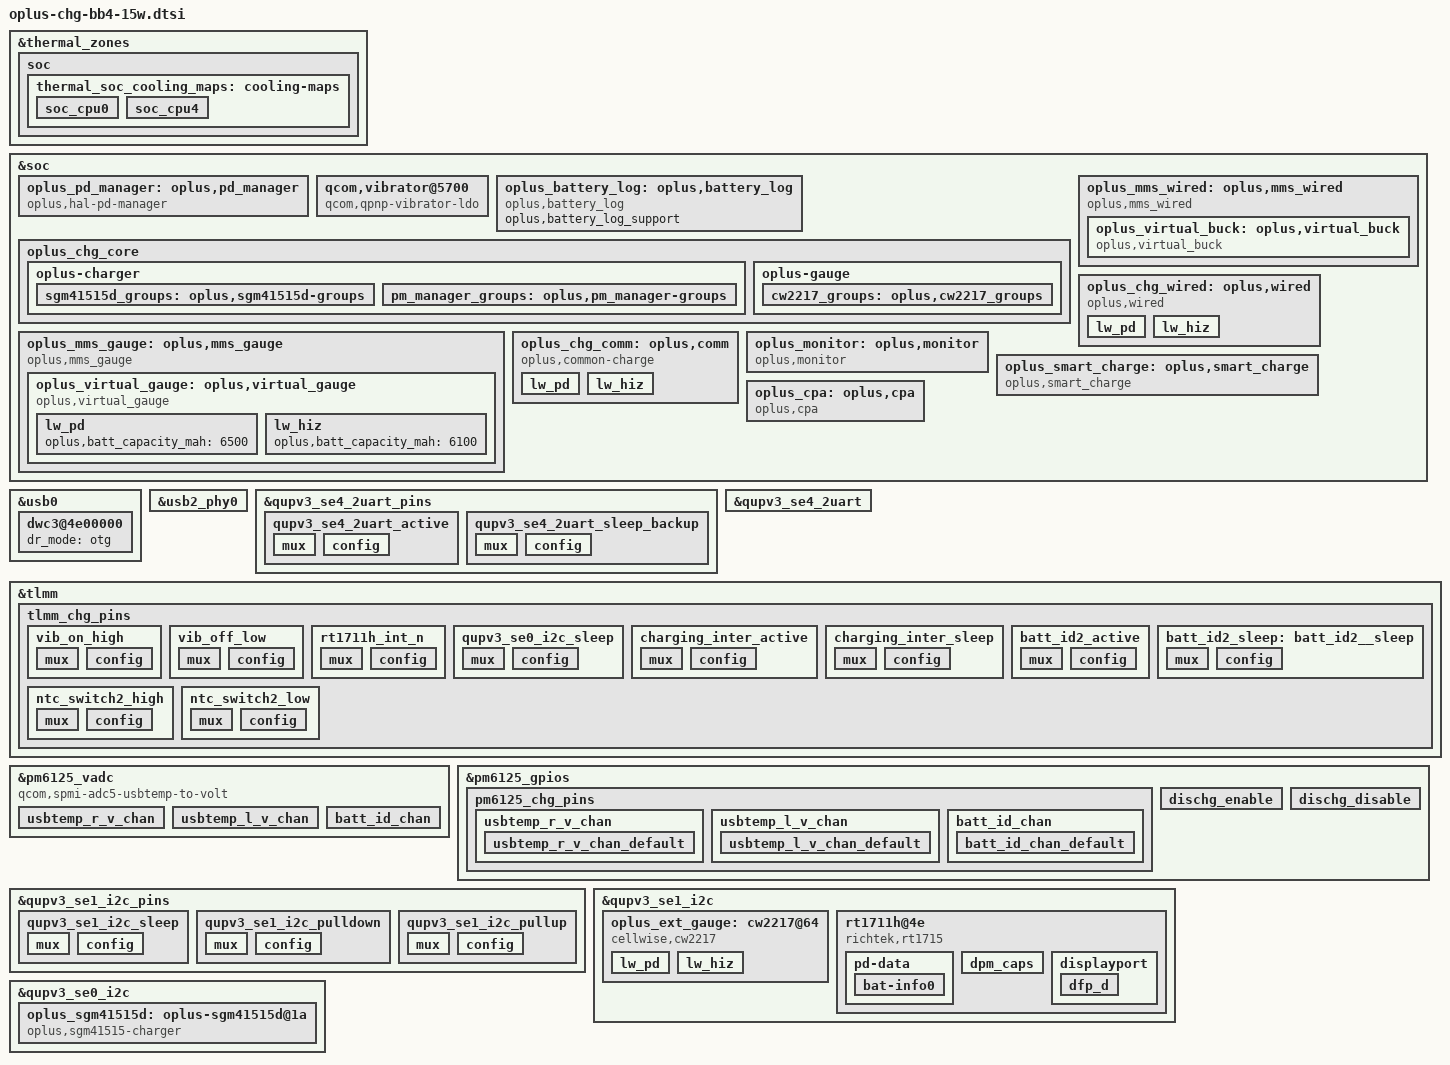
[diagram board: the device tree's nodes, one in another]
#include <dt-bindings/iio/qti_power_supply_iio.h>
#include "oplus-chg-6225.h.dtsi"

&thermal_zones {
	soc {
		thermal_soc_cooling_maps: cooling-maps {
			soc_cpu0 {
				cooling-device =
					<&CPU0 (THERMAL_MAX_LIMIT-4)
						(THERMAL_MAX_LIMIT-4)>;
			};

			soc_cpu4 {
				cooling-device =
					<&CPU4 (THERMAL_MAX_LIMIT-4)
						(THERMAL_MAX_LIMIT-4)>;
			};
		};
	};
};

&soc {
	oplus_pd_manager: oplus,pd_manager{
		compatible = "oplus,hal-pd-manager";
		oplus,ic_type = <OPLUS_CHG_IC_TYPEC>;
		oplus,ic_index = <0>;
		oplus,enable_tcpc_irq;
	};
};

&usb0 {
	dpdm-supply = <&usb2_phy0>;
	extcon = <&oplus_pd_manager>;
	#io-channel-cells = <1>;
	dwc3@4e00000 {
		dr_mode = "otg";
	};
};

&usb2_phy0 {
	qcom,param-override-seq =
		<0x67 0x6c	/* override_x0 */
		 0x87 0x70	/* override_x1 */
		 0x2e 0x74	/* override x2 */
		 0x03 0x78>;	/* override x3 */
	qcom,param-override-seq-host =
		<0x67 0x6c	/* override_x0 */
		 0xcd 0x70	/* override_x1 */
		 0x2e 0x74	/* override x2 */
		 0x03 0x78>;	/* override x3 */
};

&qupv3_se4_2uart_pins{
	qupv3_se4_2uart_active: qupv3_se4_2uart_active {
		mux {
			pins = "gpio12", "gpio13";
			function = "qup4";
		};

		config {
			pins = "gpio12", "gpio13";
			drive-strength = <2>;
			bias-disable;
		};
	};

	qupv3_se4_2uart_sleep_backup: qupv3_se4_2uart_sleep_backup {
		mux {
			pins = "gpio12", "gpio13";
			function = "gpio";
		};

		config {
			pins = "gpio12", "gpio13";
			drive-strength = <2>;
			bias-disable;
			input-enable;
		};
	};
};

&qupv3_se4_2uart {
	pinctrl-names = "default", "sleep";
	pinctrl-0 = <&qupv3_se4_2uart_active>;
	pinctrl-1 = <&qupv3_se4_2uart_sleep_backup>;
	status = "ok";
};

&tlmm {
	tlmm_chg_pins: tlmm_chg_pins {
		vib_on_high: vib_on_high {
			mux {
				pins = "gpio100";
				function = "gpio";
			};

			config {
				pins = "gpio100";
				drive-strength = <2>;
				output-high;
			};
		};
		vib_off_low: vib_off_low {
			mux {
				pins = "gpio100";
				function = "gpio";
			};

			config {
				pins = "gpio100";
				drive-strength = <2>;
				output-low;
			};
		};
		rt1711h_int_n: rt1711h_int_n {
			mux {
				pins = "gpio89";
				function = "gpio";
			};

			config {
				pins = "gpio89";
				drive-strength = <2>;
				bias-disable;
			};
		};

		qupv3_se0_i2c_sleep: qupv3_se0_i2c_sleep {
				mux {
					pins = "gpio0", "gpio1";
					function = "gpio";
				};

				config {
					pins = "gpio0", "gpio1";
					drive-strength = <2>;
					bias-no-pull;
					output-high;
				};
		};

		charging_inter_active: charging_inter_active {
				mux {
				pins = "gpio32";
				function = "gpio";
			};

			config {
				pins = "gpio32";
				drive-strength = <2>;
				bias-pull-up;
			};
		};

		charging_inter_sleep: charging_inter_sleep {
			mux {
				pins = "gpio32";
				function = "gpio";
			};

			config {
				pins = "gpio32";
				drive-strength = <2>;
				bias-pull-up;
			};
		};

		batt_id2_active: batt_id2_active {
				mux {
				pins = "gpio97";
				function = "gpio";
			};

			config {
				pins = "gpio97";
				drive-strength = <2>;
				bias-pull-up;
			};
		};

		batt_id2_sleep: batt_id2__sleep {
			mux {
				pins = "gpio97";
				function = "gpio";
			};

			config {
				pins = "gpio97";
				drive-strength = <2>;
				bias-pull-up;
			};
		};

		ntc_switch2_high: ntc_switch2_high {
			mux {
				pins = "gpio101";
				function = "gpio";
			};

			config {
				pins = "gpio101";
				drive-strength = <2>;
				output-high;
			};
		};

		ntc_switch2_low: ntc_switch2_low {
			mux {
				pins = "gpio101";
				function = "gpio";
			};

			config {
				pins = "gpio101";
				drive-strength = <2>;
				output-low;
			};
		};

	};
};

&pm6125_vadc {
	compatible = "qcom,spmi-adc5-usbtemp-to-volt";
	pinctrl-0 = <&usbtemp_r_v_chan_default &usbtemp_l_v_chan_default &batt_id_chan_default>;
	usbtemp_r_v_chan {
		reg = <ADC5_GPIO1_100K_PU>;
		label = "usbtemp_r_v_chan";
		qcom,ratiometric;
		qcom,hw-settle-time = <200>;
		qcom,pre-scaling = <1 1>;
		qcom,scale-fn-type = <ADC_SCALE_HW_CALIB_DEFAULT>;
	};

	usbtemp_l_v_chan {
		reg = <ADC5_GPIO2_100K_PU>;
		label = "usbtemp_l_v_chan";
		qcom,ratiometric;
		qcom,hw-settle-time = <200>;
		qcom,pre-scaling = <1 1>;
		qcom,scale-fn-type = <ADC_SCALE_HW_CALIB_DEFAULT>;
	};

	batt_id_chan {
		reg = <ADC5_GPIO3_100K_PU>;
		label = "batt_id_chan";
		qcom,scale-fn-type = <ADC_SCALE_HW_CALIB_DEFAULT>;
		qcom,hw-settle-time = <200>;
		qcom,pre-scaling = <1 1>;
	};
};

&pm6125_gpios {
	pm6125_chg_pins: pm6125_chg_pins {
		usbtemp_r_v_chan {
			usbtemp_r_v_chan_default: usbtemp_r_v_chan_default {
				pins = "gpio3";
				bias-high-impedance;
			};
		};

		usbtemp_l_v_chan {
			usbtemp_l_v_chan_default: usbtemp_l_v_chan_default {
				pins = "gpio4";
				bias-high-impedance;
			};
		};

		batt_id_chan {
			batt_id_chan_default: batt_id_chan_default {
				pins = "gpio6";
				bias-high-impedance;
			};
		};

	};
	dischg_enable: dischg_enable {
		pins = "gpio8";
		function = "normal";
		power-source = <0>;
		output-high;
		input-disable;
		qcom,drive-strength = <2>;
	};

	dischg_disable: dischg_disable {
		pins = "gpio8";
		function = "normal";
		power-source = <0>;
		output-low;
		input-disable;
		qcom,drive-strength = <2>;
	};
};

&qupv3_se1_i2c_pins {
	qupv3_se1_i2c_sleep: qupv3_se1_i2c_sleep {
		mux {
			pins = "gpio4", "gpio5";
			function = "gpio";
		};

		config {
			pins = "gpio4", "gpio5";
			drive-strength = <2>;
			bias-no-pull;
			output-high;
		};
	};
	qupv3_se1_i2c_pulldown: qupv3_se1_i2c_pulldown {
		mux {
			pins = "gpio4", "gpio5";
			function = "gpio";
		};

		config {
			pins = "gpio4", "gpio5";
			drive-strength = <2>;
			bias-pull-down;
			output-low;
		};
	};

	qupv3_se1_i2c_pullup: qupv3_se1_i2c_pullup {
		mux {
			pins = "gpio4", "gpio5";
			function = "gpio";
		};

		config {
			pins = "gpio4", "gpio5";
			drive-strength = <2>;
			bias-pull-up;
			input-enable;
		};
	};
};

&qupv3_se1_i2c {
	status = "okay";
	qcom,clk-freq-out = <400000>;
	pinctrl-names = "default", "sleep", "pulldown", "pullup";
	pinctrl-0 = <&qupv3_se1_i2c_active>;
	pinctrl-1 = <&qupv3_se1_i2c_sleep>;
	pinctrl-2 = <&qupv3_se1_i2c_pulldown>;
	pinctrl-3 = <&qupv3_se1_i2c_pullup>;
	oplus_ext_gauge:cw2217@64 {
		status = "okay";
		compatible = "cellwise,cw2217";
		reg = <0x64>;
		oplus,ic_index = <0>;
		oplus,ic_type = <OPLUS_CHG_IC_GAUGE>;
		qcom,cw_ui_full = <100>;
		qcom,cw_user_rsense = <5000>;
		qcom,cw_switch_config_profile;
		oplus,batt_num = <1>;
		qcom,design_capacity = <6100>;
		qcom,rated_capacity = <6100>;
		io-channels = <&pm6125_vadc ADC5_GPIO3_100K_PU>;
		io-channel-names = "batt_id_chan";
		dep-supply = <&pm6125_vadc>;
		oplus,batt_id2_gpio = <&tlmm 97 0x0>;
		pinctrl-names = "batt_id2_active", "batt_id2_sleep", "ntc_switch2_high", "ntc_switch2_low";
		pinctrl-0 = <&batt_id2_active>;
		pinctrl-1 = <&batt_id2_sleep>;
		pinctrl-2 = <&ntc_switch2_high>;
		pinctrl-3 = <&ntc_switch2_low>;
		batid_voltage_range = <70 180>;

		qcom,config_profile_data0 = /bits/ 8 <
			0x46 0x00 0x00 0x00 0x00 0x00 0x00 0x00
			0xA3 0xBE 0xBC 0xC2 0xAC 0xA3 0xD6 0xC3
			0xB2 0xF6 0xD2 0x9C 0x81 0x61 0x51 0x44
			0x3A 0x32 0x29 0x98 0x94 0xDF 0xD1 0xFF
			0xDB 0xD4 0xD7 0xD6 0xD2 0xD1 0xCE 0xCA
			0xC4 0xC3 0xD0 0xBE 0x9A 0x8F 0x84 0x75
			0x65 0x62 0x7C 0x8C 0x9D 0xA7 0x6F 0x62
			0x20 0x00 0xAB 0x10 0x00 0xB3 0x52 0x02
			0x00 0x00 0x64 0x12 0xC2 0x24 0x00 0x00
			0x00 0x00 0x00 0x00 0x00 0x00 0x00 0xA1>;
		qcom,config_profile_data1 = /bits/ 8 <
			0x46 0x00 0x00 0x00 0x00 0x00 0x00 0x00
			0xA3 0xBE 0xBC 0xC2 0xAC 0xA3 0xD6 0xC3
			0xB2 0xF6 0xD2 0x9C 0x81 0x61 0x51 0x44
			0x3A 0x32 0x29 0x98 0x94 0xDF 0xD1 0xFF
			0xDB 0xD4 0xD7 0xD6 0xD2 0xD1 0xCE 0xCA
			0xC4 0xC3 0xD0 0xBE 0x9A 0x8F 0x84 0x75
			0x65 0x62 0x7C 0x8C 0x9D 0xA7 0x6F 0x62
			0x20 0x00 0xAB 0x10 0x00 0xB3 0x52 0x02
			0x00 0x00 0x64 0x12 0xC2 0x24 0x00 0x00
			0x00 0x00 0x00 0x00 0x00 0x00 0x00 0xA1>;

		lw_pd {
			qcom,cw_switch_config_profile;
			oplus,batt_num = <1>;
			qcom,cw_ui_full = <100>;
			qcom,cw_user_rsense = <5000>;
			qcom,design_capacity = <6500>;
			qcom,rated_capacity = <6500>;
			batid_voltage_range = <70 180>;
			qcom,config_profile_data0 = /bits/ 8 <
				0x46 0x00 0x00 0x00 0x00 0x00 0x00 0x00
				0xAD 0xB2 0xB4 0xBC 0xA4 0x9F 0xDD 0xC7
				0xB4 0xFF 0xE0 0xA0 0x83 0x6A 0x58 0x4E
				0x49 0x48 0x47 0xBF 0xA9 0xDF 0xAA 0xFA
				0xD5 0xD3 0xD9 0xD6 0xD2 0xD1 0xCF 0xCA
				0xC5 0xC5 0xCC 0xC2 0x99 0x8F 0x82 0x73
				0x63 0x60 0x6F 0x8B 0xA0 0x9C 0x88 0x62
				0x20 0x00 0xAB 0x10 0x00 0xB2 0xBF 0x02
				0x00 0x00 0x64 0x16 0xC1 0xA9 0x00 0x00
				0x00 0x00 0x00 0x00 0x00 0x00 0x00 0x80>;
			qcom,config_profile_data1 = /bits/ 8 <
				0x46 0x00 0x00 0x00 0x00 0x00 0x00 0x00
				0xAD 0xB2 0xB4 0xBC 0xA4 0x9F 0xDD 0xC7
				0xB4 0xFF 0xE0 0xA0 0x83 0x6A 0x58 0x4E
				0x49 0x48 0x47 0xBF 0xA9 0xDF 0xAA 0xFA
				0xD5 0xD3 0xD9 0xD6 0xD2 0xD1 0xCF 0xCA
				0xC5 0xC5 0xCC 0xC2 0x99 0x8F 0x82 0x73
				0x63 0x60 0x6F 0x8B 0xA0 0x9C 0x88 0x62
				0x20 0x00 0xAB 0x10 0x00 0xB2 0xBF 0x02
				0x00 0x00 0x64 0x16 0xC1 0xA9 0x00 0x00
				0x00 0x00 0x00 0x00 0x00 0x00 0x00 0x80>;
		};
		lw_hiz {
			qcom,cw_switch_config_profile;
			oplus,batt_num = <1>;
			qcom,cw_ui_full = <100>;
			qcom,cw_user_rsense = <5000>;
			qcom,design_capacity = <6100>;
			qcom,rated_capacity = <6100>;
			batid_voltage_range = <70 180>;
			qcom,config_profile_data0 = /bits/ 8 <
				0x46 0x00 0x00 0x00 0x00 0x00 0x00 0x00
				0xA3 0xBE 0xBC 0xC2 0xAC 0xA3 0xD6 0xC3
				0xB2 0xF6 0xD2 0x9C 0x81 0x61 0x51 0x44
				0x3A 0x32 0x29 0x98 0x94 0xDF 0xD1 0xFF
				0xDB 0xD4 0xD7 0xD6 0xD2 0xD1 0xCE 0xCA
				0xC4 0xC3 0xD0 0xBE 0x9A 0x8F 0x84 0x75
				0x65 0x62 0x7C 0x8C 0x9D 0xA7 0x6F 0x62
				0x20 0x00 0xAB 0x10 0x00 0xB3 0x52 0x02
				0x00 0x00 0x64 0x12 0xC2 0x24 0x00 0x00
				0x00 0x00 0x00 0x00 0x00 0x00 0x00 0xA1>;
			qcom,config_profile_data1 = /bits/ 8 <
				0x46 0x00 0x00 0x00 0x00 0x00 0x00 0x00
				0xA3 0xBE 0xBC 0xC2 0xAC 0xA3 0xD6 0xC3
				0xB2 0xF6 0xD2 0x9C 0x81 0x61 0x51 0x44
				0x3A 0x32 0x29 0x98 0x94 0xDF 0xD1 0xFF
				0xDB 0xD4 0xD7 0xD6 0xD2 0xD1 0xCE 0xCA
				0xC4 0xC3 0xD0 0xBE 0x9A 0x8F 0x84 0x75
				0x65 0x62 0x7C 0x8C 0x9D 0xA7 0x6F 0x62
				0x20 0x00 0xAB 0x10 0x00 0xB3 0x52 0x02
				0x00 0x00 0x64 0x12 0xC2 0x24 0x00 0x00
				0x00 0x00 0x00 0x00 0x00 0x00 0x00 0xA1>;
		};
	};

	rt1711h@4e {
		compatible = "richtek,rt1715";
		reg = <0x4e>;
		status = "okay";
		tcpc-dual,supported_modes = <0>; /* 0: dfp/ufp, */
						 /* 1: dfp, 2: ufp */
		rt-tcpc,name = "type_c_port0"; /* tcpc_device's name */
		rt-tcpc,role_def = <1>; /* 0: Unknown, 1: SNK, 2: SRC */
					/* 3: DRP, 4: Try.SRC, 5: Try.SNK */
		rt-tcpc,rp_level = <0>; /* 0: Default, 1: 1.5, 2: 3.0 */
		rt1711pd,intr_gpio = <&tlmm 89 0x0>;
		rt1711pd,intr_gpio_num = <89>;
		rt,disable_irq_reset;
		charger = <&oplus_sgm41515d>;
		pinctrl-names = "default";
		pinctrl-0 = <&rt1711h_int_n>;
		pd-data {
			pd,vid = <0x29cf>;
			pd,pid = <0x1711>;
			pd,source-cap-ext = /bits/ 8 <0xcf 0x29 0x11 0x17
						      0x00 0x00 0x00 0x00
						      0x00 0x00 0x00 0x00
						      0x00 0x00 0x00 0x00
						      0x00 0x00 0x00 0x00
						      0x00 0x00 0x01 0x02
						      0x00>;
			pd,sink-cap-ext = /bits/ 8 <0xcf 0x29 0x11 0x17
					0x00 0x00 0x00 0x00
					0x01 0x00 0x00 0x00
					0x00 0x00 0x00 0x00
					0x01 0x00 0x00 0x00
					0x00 0x00 0x00 0x00>;
			pd,mfrs = "RichtekTCPC";

			/*
			 *	VSAFE5V = 0, MAX_POWER = 1, CUSTOM = 2,
			 *	MAX_POWER_LV = 0x21, MAX_POWER_LVIC = 0x31
			 *	MAX_POWER_HV = 0x41, MAX_POWER_HVIC = 0x51
			 */
			pd,charging_policy = <0>;

			/*
			 * Fixed 5V, 500 mA <0x00019032>
			 * Fixed 5V, 1A <0x00019064>
			 * Fixed 5V, 2A <0x000190c8>
			 * Fixed 5V, 3A <0x0001912c>
			 * Fixed 9V, 500 mA <0x0002d032>
			 * Fixed 9V, 1A <0x0002d064>
			 * Fixed 9V, 2A <0x0002d0c8>
			 * Fixed 9V, 3A <0x0002d12c>
			 * Variable 5-9V, 1A <0x8642d064>
			 * Variable 5-9V, 2A <0x8642d0c8>
			 * Variable 5-9V, 3A <0x8642d12c>
			 */
			pd,source-pdo-size = <1>;
			pd,source-pdo-data = <0x00019064>;
			pd,sink-pdo-size = <1>;
			pd,sink-pdo-data = <0x0001912c>;

			pd,id-vdo-size = <6>;
			pd,id-vdo-data = <0xd14029cf 0x0 0x17110000
					  0x61000000 0x0 0x41000000>;

			bat,nr = <1>;
			pd,country_nr = <0>;

			bat-info0 {
				bat,vid = <0x29cf>;
				bat,pid = <0x1711>;
				bat,mfrs = "bat1";
				bat,design_cap = <3000>;
			};
		};
		dpm_caps {
			local_dr_power;
			local_dr_data;
			local_usb_comm;
			local_no_suspend;
			attempt_discover_cable;
			attempt_discover_id;
			attempt_discover_svid;

			/* 0: disable, 1: prefer_snk, 2: prefer_src */
			pr_check = <0>;
			/* 0: disable, 1: prefer_ufp, 2: prefer_dfp */
			dr_check = <0>;
		};
		displayport {
			/* connection type = "both", "ufp_d", "dfp_d" */
			1st_connection = "dfp_d";
			2nd_connection = "dfp_d";
			signal,dp_v13;
			typec,receptacle;
			dfp_d {
				pin_assignment,mode_c;
				pin_assignment,mode_d;
				pin_assignment,mode_e;
			};
		};
	};
};

/* load vibrator for rm pmic */
&soc {
	qcom,vibrator@5700 {
		compatible = "qcom,qpnp-vibrator-ldo";
		reg = <0x5700 0x100>;
		qcom,vib-ldo-volt-uv = <3000000>;
		qcom,disable-overdrive;
		qcom,vib-type = <1>;	/* 0:ldo 1:gpio */
		status = "okay";
		qcom,vibrator_switch-gpio = <&tlmm 100 0x00>;
		pinctrl-names = "vib_on_high", "vib_off_low";
		pinctrl-0 = <&vib_on_high>;
		pinctrl-1 = <&vib_off_low >;
	};
};

&qupv3_se0_i2c {
	status = "okay";
	pinctrl-0 = <&qupv3_se0_i2c_active>;
	pinctrl-1 = <&qupv3_se0_i2c_sleep>;
	qcom,clk-freq-out = <400000>;
	oplus,i2c-auto-suspend-delay-ms = <3000>;
	oplus_sgm41515d:oplus-sgm41515d@1a {
		status = "okay";
		compatible = "oplus,sgm41515-charger";
		reg = <0x1a>;
		dpdm-supply = <&usb2_phy0>;
		oplus,dischg-gpio = <&pm6125_gpios 8 0x00>;
		oplus,event-gpio = <&tlmm 32 0x00>;
		qcom,ntc-switch-gpio-amux = <&tlmm 101 0x00>;
		pinctrl-names = "event_default", "charging_inter_sleep",
					"dischg_enable", "dischg_disable";
		pinctrl-0 = <&charging_inter_active>;
		pinctrl-1 = <&charging_inter_sleep>;
		pinctrl-2 = <&dischg_enable>;
		pinctrl-3 = <&dischg_disable>;
		oplus,not_support_usb_btb;
		oplus,ic_index = <0>;
		oplus,ic_type = <OPLUS_CHG_IC_BUCK>;
		io-channels = <&pm6125_vadc ADC5_GPIO3_100K_PU>;
		io-channel-names = "chg_temp_adc";
		#include "BB4_ntc.h.dtsi"
	};

};

&soc {
	oplus_battery_log: oplus,battery_log {
		compatible = "oplus,battery_log";
		oplus,battery_log_support;
	};
	oplus_chg_core {
		oplus,chg_framework_v2;
		oplus,smart_charging_screenoff;
		oplus,chg_spec_version = <OPLUS_CHG_SPEC_VER_V3P7>;
		oplus,battery_type_by_cmdline;
		oplus-charger {
			sgm41515d_groups: oplus,sgm41515d-groups {
				functions = <
					OPLUS_IC_FUNC_INIT
					OPLUS_IC_FUNC_EXIT
					OPLUS_IC_FUNC_REG_DUMP
					OPLUS_IC_FUNC_SMT_TEST
					OPLUS_IC_FUNC_BUCK_INPUT_PRESENT
					OPLUS_IC_FUNC_BUCK_INPUT_SUSPEND
					OPLUS_IC_FUNC_BUCK_INPUT_IS_SUSPEND
					OPLUS_IC_FUNC_BUCK_OUTPUT_SUSPEND
					OPLUS_IC_FUNC_BUCK_OUTPUT_IS_SUSPEND
					OPLUS_IC_FUNC_BUCK_SET_ICL
					OPLUS_IC_FUNC_BUCK_GET_ICL
					OPLUS_IC_FUNC_BUCK_SET_FCC
					OPLUS_IC_FUNC_BUCK_SET_FV
					OPLUS_IC_FUNC_BUCK_SET_ITERM
					OPLUS_IC_FUNC_BUCK_SET_RECHG_VOL
					OPLUS_IC_FUNC_BUCK_GET_INPUT_CURR
					OPLUS_IC_FUNC_BUCK_GET_INPUT_VOL
					OPLUS_IC_FUNC_OTG_BOOST_ENABLE
					OPLUS_IC_FUNC_SET_OTG_BOOST_VOL
					OPLUS_IC_FUNC_SET_OTG_BOOST_CURR_LIMIT
					OPLUS_IC_FUNC_BUCK_AICL_ENABLE
					OPLUS_IC_FUNC_BUCK_AICL_RERUN
					OPLUS_IC_FUNC_BUCK_AICL_RESET
					OPLUS_IC_FUNC_BUCK_GET_CHARGER_TYPE
					OPLUS_IC_FUNC_BUCK_RERUN_BC12
					OPLUS_IC_FUNC_BUCK_QC_DETECT_ENABLE
					OPLUS_IC_FUNC_BUCK_SET_QC_CONFIG
					OPLUS_IC_FUNC_BUCK_SHIPMODE_ENABLE
					OPLUS_IC_FUNC_BUCK_GET_USB_BTB_TEMP
					OPLUS_IC_FUNC_BUCK_GET_BATT_BTB_TEMP
					OPLUS_IC_FUNC_BUCK_SET_AICL_POINT
					OPLUS_IC_FUNC_BUCK_HARDWARE_INIT
					OPLUS_IC_FUNC_BUCK_KICK_WDT
					OPLUS_IC_FUNC_POWER_ROLE_SWAP
					OPLUS_IC_FUNC_SET_USB_DISCHG_ENABLE
				>;
				virqs = <
					OPLUS_IC_VIRQ_ERR
					OPLUS_IC_VIRQ_PLUGIN
					OPLUS_IC_VIRQ_CHG_TYPE_CHANGE
					OPLUS_IC_VIRQ_BC12_COMPLETED
				>;
			};
			pm_manager_groups: oplus,pm_manager-groups {
				functions = <
					OPLUS_IC_FUNC_INIT
					OPLUS_IC_FUNC_EXIT
					OPLUS_IC_FUNC_REG_DUMP
					OPLUS_IC_FUNC_SMT_TEST
					OPLUS_IC_FUNC_BUCK_GET_CHARGER_TYPE
					OPLUS_IC_FUNC_BUCK_GET_CC_ORIENTATION
					OPLUS_IC_FUNC_BUCK_SET_PD_CONFIG
					OPLUS_IC_FUNC_GET_TYPEC_ROLE
					OPLUS_IC_FUNC_GET_TYPEC_MODE
					OPLUS_IC_FUNC_SET_TYPEC_MODE
					OPLUS_IC_FUNC_GET_CHARGER_VOL_MAX
					OPLUS_IC_FUNC_GET_CHARGER_VOL_MIN
					OPLUS_IC_FUNC_GET_CHARGER_CURR_MAX
					OPLUS_IC_FUNC_BUCK_BC12_COMPLETED
					OPLUS_IC_FUNC_GET_OTG_ENABLE
					OPLUS_IC_FUNC_IS_OPLUS_SVID
					OPLUS_IC_FUNC_GET_DATA_ROLE
					OPLUS_IC_FUNC_FIXED_PDO_SET
					OPLUS_IC_FUNC_PPS_PDO_SET
					OPLUS_IC_FUNC_PPS_GET_PDO_INFO
				>;
				virqs = <
					OPLUS_IC_VIRQ_ERR
					OPLUS_IC_VIRQ_CHG_TYPE_CHANGE
					OPLUS_IC_VIRQ_SVID
					OPLUS_IC_VIRQ_VOLTAGE_CHANGED
					OPLUS_IC_VIRQ_CURRENT_CHANGED
					OPLUS_IC_VIRQ_OTG_ENABLE
					OPLUS_IC_VIRQ_DATA_ROLE_CHANGED
					OPLUS_IC_VIRQ_PR_SWAP
				>;
			};
		};
		oplus-gauge {
			cw2217_groups: oplus,cw2217_groups {
				functions = <
					OPLUS_IC_FUNC_INIT
					OPLUS_IC_FUNC_EXIT
					OPLUS_IC_FUNC_REG_DUMP
					OPLUS_IC_FUNC_GAUGE_GET_BATT_VOL
					OPLUS_IC_FUNC_GAUGE_GET_BATT_MAX
					OPLUS_IC_FUNC_GAUGE_GET_BATT_MIN
					OPLUS_IC_FUNC_GAUGE_GET_BATT_CURR
					OPLUS_IC_FUNC_GAUGE_GET_BATT_TEMP
					OPLUS_IC_FUNC_GAUGE_GET_BATT_SOC
					OPLUS_IC_FUNC_GAUGE_GET_BATT_FCC
					OPLUS_IC_FUNC_GAUGE_GET_BATT_CC
					OPLUS_IC_FUNC_GAUGE_GET_BATT_RM
					OPLUS_IC_FUNC_GAUGE_GET_BATT_SOH
					OPLUS_IC_FUNC_GAUGE_GET_BATT_AUTH
					OPLUS_IC_FUNC_GAUGE_GET_BATT_HMAC
					OPLUS_IC_FUNC_GAUGE_SET_BATT_FULL
					OPLUS_IC_FUNC_GAUGE_GET_BATT_NUM
					OPLUS_IC_FUNC_GAUGE_GET_DEVICE_TYPE
					OPLUS_IC_FUNC_GAUGE_GET_AFI_UPDATE_DONE
					OPLUS_IC_FUNC_GAUGE_GET_DEVICE_TYPE_FOR_BCC
					OPLUS_IC_FUNC_GAUGE_GET_QMAX
					OPLUS_IC_FUNC_GAUGE_GET_REG_INFO
					OPLUS_IC_FUNC_GAUGE_GET_BATT_EXIST
					OPLUS_IC_FUNC_GAUGE_GET_DEC_FG_TYPE
					OPLUS_IC_FUNC_GAUGE_GET_DEC_CV_SOH
				>;
				virqs = <
					OPLUS_IC_VIRQ_ERR
					OPLUS_IC_VIRQ_OFFLINE
					OPLUS_IC_VIRQ_RESUME
				>;
			};
		};
	};
};

&soc {
	oplus_mms_wired: oplus,mms_wired {
		compatible = "oplus,mms_wired";
		oplus,buck_ic = <&oplus_virtual_buck>;
		oplus,adc_info_name = "855";
		high-temp-scheme;
		oplus_spec,usbtemp_batttemp_gap = <12>;
		oplus,support_usbtemp_protect_v2;
		oplus_spec,usbtemp_batt_temp_low = <50>;
		oplus_spec,usbtemp_batt_temp_high = <50>;
		oplus_spec,usbtemp_batt_temp_over_hot = <60>;
		oplus_spec,usbtemp_ntc_temp_low = <57>;
		oplus_spec,usbtemp_ntc_temp_high = <69>;
		oplus_spec,usbtemp_temp_gap_low_with_batt_temp = <7>;
		oplus_spec,usbtemp_temp_gap_with_batt_temp_in_over_hot = <15>;
		oplus_spec,usbtemp_temp_gap_high_with_batt_temp = <12>;
		oplus_spec,usbtemp_temp_gap_low_without_batt_temp = <12>;
		oplus_spec,usbtemp_temp_gap_high_without_batt_temp = <24>;
		oplus_spec.usbtemp_rise_fast_temp_low = <3>;
		oplus_spec,usbtemp_rise_fast_temp_high = <3>;
		oplus_spec,usbtemp_rise_fast_temp_count_low = <30>;
		oplus_spec,usbtemp_rise_fast_temp_count_high = <20>;
		oplus_spec,usbtemp_cool_down_ntc_low = <54>;
		oplus_spec,usbtemp_cool_down_ntc_high = <65>;
		oplus_spec,usbtemp_cool_down_gap_low = <12>;
		oplus_spec,usbtemp_cool_down_gap_high = <20>;
		oplus_spec,usbtemp_cool_down_recover_ntc_low = <48>;
		oplus_spec,usbtemp_cool_down_recover_ntc_high = <60>;
		oplus_spec,usbtemp_cool_down_recover_gap_low = <6>;
		oplus_spec,usbtemp_cool_down_recover_gap_high = <15>;
		oplus_spec,usbtemp_otg_cc_boot_current_limit = <1500>;
		oplus_virtual_buck: oplus,virtual_buck {
			compatible = "oplus,virtual_buck";
			oplus,buck_ic = <&oplus_sgm41515d &oplus_pd_manager>;
			oplus,buck_ic_index = <0 1>;
			oplus,buck_ic_current_ratio = <100 0>;
			oplus,buck_ic_connect = <OPLUS_CHG_IC_CONNECT_PARALLEL>;
			oplus,main_charger = <0>;
			oplus,buck_ic_func_group = <&sgm41515d_groups &pm_manager_groups>;
			oplus,ic_type = <OPLUS_CHG_IC_VIRTUAL_BUCK>;
			oplus,ic_index = <0>;
			oplus,uart_tx-gpio = <&tlmm 12 0x00>;
			oplus,uart_rx-gpio = <&tlmm 13 0x00>;
			oplus,usbtemp_conversion_ratio = <10>;
			oplus,ntc_switch_usbtemp_r;
			pinctrl-names = "usbtemp_l_gpio_default", "usbtemp_r_gpio_default";
			pinctrl-0 = <&usbtemp_l_v_chan_default>;
			pinctrl-1 = <&usbtemp_r_v_chan_default>;
			io-channels = <&pm6125_vadc ADC5_GPIO2_100K_PU>,
						<&pm6125_vadc ADC5_GPIO1_100K_PU>;
			io-channel-names = "usb_temp_adc_l", "usb_temp_adc_r";
		};
	};
	oplus_mms_gauge: oplus,mms_gauge {
		compatible = "oplus,mms_gauge";
		oplus,gauge_ic = <&oplus_virtual_gauge>;
		oplus,topic-update-interval = <10000>;
		oplus_virtual_gauge: oplus,virtual_gauge {
			compatible = "oplus,virtual_gauge";
			oplus,gauge_ic = <&oplus_ext_gauge>;
			oplus,gauge_ic_index = <0>;
			oplus,gauge_ic_func_group = <&cw2217_groups>;
			oplus,ic_type = <OPLUS_CHG_IC_VIRTUAL_GAUGE>;
			oplus,ic_index = <0>;
			oplus,batt_capacity_mah = <6100>;
			lw_pd {
				oplus,batt_capacity_mah = <6500>;
			};
			lw_hiz {
				oplus,batt_capacity_mah = <6100>;
			};
		};
	};
};

&soc {
	oplus_chg_wired: oplus,wired {
		compatible = "oplus,wired";
		oplus_spec,vbatt_pdqc_to_5v_thr = <4500>;
		oplus_spec,vbatt_pdqc_to_9v_thr = <3000>;
		oplus_spec,pd-iclmax-ma = <3000>;
		oplus_spec,qc-iclmax-ma = <3000>;
		oplus_spec,non-standard-ibatmax-ma = <500>;
		oplus_spec,input-power-mw = <
			2500		/* OPLUS_WIRED_CHG_MODE_UNKNOWN */
			2500		/* OPLUS_WIRED_CHG_MODE_SDP */
			7500		/* OPLUS_WIRED_CHG_MODE_CDP */
			15000		/* OPLUS_WIRED_CHG_MODE_DCP */
			15000		/* OPLUS_WIRED_CHG_MODE_VOOC */
			15000		/* OPLUS_WIRED_CHG_MODE_QC */
			15000		/* OPLUS_WIRED_CHG_MODE_PD */
		>;
		oplus_spec,led_on-fccmax-ma = <0 892 2677 3300 3300 3300 3300 1000 0>;
		oplus_spec,fccmax-ma-lv = <
			0 892 2200 2200 2200 2200 2200 2200 0	/* OPLUS_WIRED_CHG_MODE_UNKNOWN */
			0 600 600  600  600  600  600  600  0	/* OPLUS_WIRED_CHG_MODE_SDP */
			0 892 1600 1600 1600 1600 1600 1600 0	/* OPLUS_WIRED_CHG_MODE_CDP */
			0 892 2677 3300 3300 3300 3300 3272 0	/* OPLUS_WIRED_CHG_MODE_DCP */
			0 892 2677 3300 3300 3300 3300 3272 0	/* OPLUS_WIRED_CHG_MODE_VOOC */
			0 892 2677 3300 3300 3300 3300 3272 0	/* OPLUS_WIRED_CHG_MODE_QC */
			0 892 2677 3300 3300 3300 3300 3272 0	/* OPLUS_WIRED_CHG_MODE_PD */
		>;
		oplus_spec,fccmax-ma-hv = <
			0 892 1487 2200 2200 2200 2200 2200 0	/* OPLUS_WIRED_CHG_MODE_UNKNOWN */
			0 600 600  600  600  600  600  600  0	/* OPLUS_WIRED_CHG_MODE_SDP */
			0 892 1487 1600 1600 1600 1600 1600 0	/* OPLUS_WIRED_CHG_MODE_CDP */
			0 892 1487 3300 3300 3300 3300 3272 0	/* OPLUS_WIRED_CHG_MODE_DCP */
			0 892 1487 3300 3300 3300 3300 3272 0	/* OPLUS_WIRED_CHG_MODE_VOOC */
			0 892 1487 3300 3300 3300 3300 3272 0	/* OPLUS_WIRED_CHG_MODE_QC */
			0 892 1487 3300 3300 3300 3300 3272 0	/* OPLUS_WIRED_CHG_MODE_PD */
		>;
		oplus_spec,cool_down_sale_pdqc_vol_mv = <5000>;
		oplus_spec,cool_down_sale_pdqc_curr_ma = <1200>;
		oplus_spec,cool_down_pdqc_vol_mv = <5000 5000 5000 5000 5000>;
		oplus_spec,cool_down_pdqc_curr_ma = <1200 1500 2000 2500 3000>;
		oplus_spec,cool_down_normal_curr_ma = <1200 1500 2000 2500 3000>;
		oplus_spec,vbus_ov_thr_mv = <10000 10000>;
		oplus_spec,vbus_uv_thr_mv = <4300 4300>;
		oplus,pd_strategy_name = "cgcl";
		oplus,pd_strategy_data = < OPLUS_STRATEGY_USE_SHELL_TEMP
					   0   420 3000 1 0
					   410 430 1500 2 0
					   420 440 1200 2 1>;

		oplus,dcp_strategy_name = "cgcl";
		oplus,dcp_strategy_data = < OPLUS_STRATEGY_USE_SHELL_TEMP
					   0   420 3000 1 0
					   410 430 1500 2 0
					   420 440 1200 2 1>;

		/* id2 pulldown: Single cell */
		lw_pd {
			oplus_spec,vbatt_pdqc_to_5v_thr = <4500>;
			oplus_spec,vbatt_pdqc_to_9v_thr = <3000>;
			oplus_spec,pd-iclmax-ma = <3000>;
			oplus_spec,qc-iclmax-ma = <3000>;
			oplus_spec,non-standard-ibatmax-ma = <500>;
			oplus_spec,input-power-mw = <
				2500		/* OPLUS_WIRED_CHG_MODE_UNKNOWN */
				2500		/* OPLUS_WIRED_CHG_MODE_SDP */
				7500		/* OPLUS_WIRED_CHG_MODE_CDP */
				15000		/* OPLUS_WIRED_CHG_MODE_DCP */
				15000		/* OPLUS_WIRED_CHG_MODE_VOOC */
				15000		/* OPLUS_WIRED_CHG_MODE_QC */
				15000		/* OPLUS_WIRED_CHG_MODE_PD */
			>;
			oplus_spec,led_on-fccmax-ma = <0 950 2850 3300 3300 3300 3300 1000 0>;
			oplus_spec,fccmax-ma-lv = <
				0 950 2200 2200 2200 2200 2200 2200 0	/* OPLUS_WIRED_CHG_MODE_UNKNOWN */
				0 600 600  600  600  600  600  600  0	/* OPLUS_WIRED_CHG_MODE_SDP */
				0 950 1600 1600 1600 1600 1600 1600 0	/* OPLUS_WIRED_CHG_MODE_CDP */
				0 950 2850 3300 3300 3300 3300 3300 0	/* OPLUS_WIRED_CHG_MODE_DCP */
				0 950 2850 3300 3300 3300 3300 3300 0	/* OPLUS_WIRED_CHG_MODE_VOOC */
				0 950 2850 3300 3300 3300 3300 3300 0	/* OPLUS_WIRED_CHG_MODE_QC */
				0 950 2850 3300 3300 3300 3300 3300 0	/* OPLUS_WIRED_CHG_MODE_PD */
			>;
			oplus_spec,fccmax-ma-hv = <
				0 950 1583 2200 2200 2200 2200 2200 0	/* OPLUS_WIRED_CHG_MODE_UNKNOWN */
				0 600 600  600  600  600  600  600  0	/* OPLUS_WIRED_CHG_MODE_SDP */
				0 950 1583 1600 1600 1600 1600 1600 0	/* OPLUS_WIRED_CHG_MODE_CDP */
				0 950 1583 3300 3300 3300 3300 3300 0	/* OPLUS_WIRED_CHG_MODE_DCP */
				0 950 1583 3300 3300 3300 3300 3300 0	/* OPLUS_WIRED_CHG_MODE_VOOC */
				0 950 1583 3300 3300 3300 3300 3300 0	/* OPLUS_WIRED_CHG_MODE_QC */
				0 950 1583 3300 3300 3300 3300 3300 0	/* OPLUS_WIRED_CHG_MODE_PD */
			>;
			oplus_spec,cool_down_sale_pdqc_vol_mv = <5000>;
			oplus_spec,cool_down_sale_pdqc_curr_ma = <1200>;
			oplus_spec,cool_down_pdqc_vol_mv = <5000 5000 5000 5000 5000>;
			oplus_spec,cool_down_pdqc_curr_ma = <1200 1500 2000 2500 3000>;
			oplus_spec,cool_down_normal_curr_ma = <1200 1500 2000 2500 3000>;
			oplus_spec,vbus_ov_thr_mv = <10000 10000>;
			oplus_spec,vbus_uv_thr_mv = <4300 4300>;
			oplus,pd_strategy_name = "cgcl";
			oplus,pd_strategy_data = < OPLUS_STRATEGY_USE_SHELL_TEMP
						0   420 3000 1 0
						410 430 1500 2 0
						420 440 1200 2 1>;

			oplus,dcp_strategy_name = "cgcl";
			oplus,dcp_strategy_data = < OPLUS_STRATEGY_USE_SHELL_TEMP
						0   420 3000 1 0
						410 430 1500 2 0
						420 440 1200 2 1>;
		};

		/* id2 float: Dual cell */
		lw_hiz {
			oplus_spec,vbatt_pdqc_to_5v_thr = <4500>;
			oplus_spec,vbatt_pdqc_to_9v_thr = <3000>;
			oplus_spec,pd-iclmax-ma = <3000>;
			oplus_spec,qc-iclmax-ma = <3000>;
			oplus_spec,non-standard-ibatmax-ma = <500>;
			oplus_spec,input-power-mw = <
				2500		/* OPLUS_WIRED_CHG_MODE_UNKNOWN */
				2500		/* OPLUS_WIRED_CHG_MODE_SDP */
				7500		/* OPLUS_WIRED_CHG_MODE_CDP */
				15000		/* OPLUS_WIRED_CHG_MODE_DCP */
				15000		/* OPLUS_WIRED_CHG_MODE_VOOC */
				15000		/* OPLUS_WIRED_CHG_MODE_QC */
				15000		/* OPLUS_WIRED_CHG_MODE_PD */
			>;
			oplus_spec,led_on-fccmax-ma = <0 892 2677 3300 3300 3300 3300 1000 0>;
			oplus_spec,fccmax-ma-lv = <
				0 892 2200 2200 2200 2200 2200 2200 0	/* OPLUS_WIRED_CHG_MODE_UNKNOWN */
				0 600 600  600  600  600  600  600  0	/* OPLUS_WIRED_CHG_MODE_SDP */
				0 892 1600 1600 1600 1600 1600 1600 0	/* OPLUS_WIRED_CHG_MODE_CDP */
				0 892 2677 3300 3300 3300 3300 3272 0	/* OPLUS_WIRED_CHG_MODE_DCP */
				0 892 2677 3300 3300 3300 3300 3272 0	/* OPLUS_WIRED_CHG_MODE_VOOC */
				0 892 2677 3300 3300 3300 3300 3272 0	/* OPLUS_WIRED_CHG_MODE_QC */
				0 892 2677 3300 3300 3300 3300 3272 0	/* OPLUS_WIRED_CHG_MODE_PD */
			>;
			oplus_spec,fccmax-ma-hv = <
				0 892 1487 2200 2200 2200 2200 2200 0	/* OPLUS_WIRED_CHG_MODE_UNKNOWN */
				0 600 600  600  600  600  600  600  0	/* OPLUS_WIRED_CHG_MODE_SDP */
				0 892 1487 1600 1600 1600 1600 1600 0	/* OPLUS_WIRED_CHG_MODE_CDP */
				0 892 1487 3300 3300 3300 3300 3272 0	/* OPLUS_WIRED_CHG_MODE_DCP */
				0 892 1487 3300 3300 3300 3300 3272 0	/* OPLUS_WIRED_CHG_MODE_VOOC */
				0 892 1487 3300 3300 3300 3300 3272 0	/* OPLUS_WIRED_CHG_MODE_QC */
				0 892 1487 3300 3300 3300 3300 3272 0	/* OPLUS_WIRED_CHG_MODE_PD */
			>;
			oplus_spec,cool_down_sale_pdqc_vol_mv = <5000>;
			oplus_spec,cool_down_sale_pdqc_curr_ma = <1200>;
			oplus_spec,cool_down_pdqc_vol_mv = <5000 5000 5000 5000 5000>;
			oplus_spec,cool_down_pdqc_curr_ma = <1200 1500 2000 2500 3000>;
			oplus_spec,cool_down_normal_curr_ma = <1200 1500 2000 2500 3000>;
			oplus_spec,vbus_ov_thr_mv = <10000 10000>;
			oplus_spec,vbus_uv_thr_mv = <4300 4300>;
			oplus,pd_strategy_name = "cgcl";
			oplus,pd_strategy_data = < OPLUS_STRATEGY_USE_SHELL_TEMP
						0   420 3000 1 0
						410 430 1500 2 0
						420 440 1200 2 1>;

			oplus,dcp_strategy_name = "cgcl";
			oplus,dcp_strategy_data = < OPLUS_STRATEGY_USE_SHELL_TEMP
						0   420 3000 1 0
						410 430 1500 2 0
						420 440 1200 2 1>;
		};
	};
	oplus_chg_comm: oplus,comm {
		compatible = "oplus,common-charge";
		oplus_spec,dec_step = <20>;
		oplus_spec,dec-vol-cc-full-thr = <0 400 600 800 1000 1200>;
		oplus_spec,dec-vol-fv-full-mv = <0 20 20 40 40 40>;
		oplus_spec,batt-them-thr = <(-100) 0 50 120 160 350 450 530>;
		oplus_spec,iterm-ma = <327>;
		oplus_spec,removed_bat_decidegc = <390>; /*-39 degree*/
		oplus_spec,fv-mv = <4450 4450 4450 4450 4450 4450 4450 4130 4130>;
		oplus_spec,sw-fv-mv = <4400 4400 4400 4400 4400 4400 4400 4080 4080>;
		oplus_spec,hw-fv-inc-mv = <0 18 18 18 18 18 18 18 0>;
		oplus_spec,sw-over-fv-mv = <4460 4460 4460 4460 4460 4460 4460 4140 4140>;
		oplus_spec,sw-over-fv-dec-mv = <8>;
		oplus_spec,non-standard-sw-fv-mv = <3930>;
		oplus_spec,non-standard-fv-mv = <3980>;
		oplus_spec,non-standard-hw-fv-inc-mv = <18>;
		oplus_spec,non-standard-sw-over-fv-mv = <3990>;
		oplus_spec,non-standard-vbatdet-mv = <3680>;
		oplus_spec,wired-vbatdet-mv = <0 4150 4250 4350 4350 4350 4350 4030 0>;
		oplus_spec,fcc-gear-thr-mv = <4180>;
		oplus_spec,vbatt-ov-thr-mv = <4600>;
		oplus_spec,full_pre_ffc_judge;
		oplus_spec,full-pre-ffc-mv = <4445>;
		oplus_spec,vbat_uv_thr_mv = <3300>;
		oplus_spec,vbat_charging_uv_thr_mv = <3200>;
		/*If use subboard NTC as battery temp, config it as 20, otherwise 0 */
		oplus_spec,tbatt_power_off_cali_temp = <0>;
		oplus_spec,poweroff_high_batt_temp = <720>;
		oplus_spec,poweroff_emergency_batt_temp = <770>;
		oplus,ui_soc_decimal_speedmin = <20>;
		oplus,gauge_stuck_jump_support;
		oplus,gauge_stuck_threshold = <15>;
		oplus,gauge_stuck_time = <50>;
		oplus,smooth_switch;
		oplus,reserve_chg_soc = <2>;
		oplus,vooc_dis_show_ui_power;
		oplus_spec,batt_full_time = <300>;
		/* id2 pulldown: Single cell */
		lw_pd {
			oplus_spec,dec_step = <20>;
			oplus_spec,dec-vol-cc-full-thr = <0 400 600 800 1000 1200>;
			oplus_spec,dec-vol-fv-full-mv = <0 20 20 40 40 40>;
			oplus_spec,batt-them-thr = <(-100) 0 50 120 160 350 450 530>;
			oplus_spec,iterm-ma = <327>;
			oplus_spec,removed_bat_decidegc = <390>; /*-39 degree*/
			oplus_spec,fv-mv = <4450 4450 4450 4450 4450 4450 4450 4130 4130>;
			oplus_spec,sw-fv-mv = <4400 4400 4400 4400 4400 4400 4400 4080 4080>;
			oplus_spec,hw-fv-inc-mv = <0 18 18 18 18 18 18 18 0>;
			oplus_spec,sw-over-fv-mv = <4460 4460 4460 4460 4460 4460 4460 4140 4140>;
			oplus_spec,sw-over-fv-dec-mv = <8>;
			oplus_spec,non-standard-sw-fv-mv = <3930>;
			oplus_spec,non-standard-fv-mv = <3980>;
			oplus_spec,non-standard-hw-fv-inc-mv = <18>;
			oplus_spec,non-standard-sw-over-fv-mv = <3990>;
			oplus_spec,non-standard-vbatdet-mv = <3680>;
			oplus_spec,wired-vbatdet-mv = <0 4150 4250 4350 4350 4350 4350 4030 0>;
			oplus_spec,fcc-gear-thr-mv = <4180>;
			oplus_spec,vbatt-ov-thr-mv = <4600>;
			oplus_spec,full_pre_ffc_judge;
			oplus_spec,full-pre-ffc-mv = <4445>;
			oplus_spec,vbat_uv_thr_mv = <3300>;
			oplus_spec,vbat_charging_uv_thr_mv = <3200>;
			/*If use subboard NTC as battery temp, config it as 20, otherwise 0 */
			oplus_spec,tbatt_power_off_cali_temp = <0>;
			oplus_spec,poweroff_high_batt_temp = <720>;
			oplus_spec,poweroff_emergency_batt_temp = <770>;
			oplus,ui_soc_decimal_speedmin = <20>;
			oplus,gauge_stuck_jump_support;
			oplus,gauge_stuck_threshold = <15>;
			oplus,gauge_stuck_time = <50>;
			oplus,smooth_switch;
			oplus,reserve_chg_soc = <2>;
			oplus,vooc_dis_show_ui_power;
			oplus_spec,batt_full_time = <300>;
		};

		/* id2 float: Dual cell */
		lw_hiz {
			oplus_spec,dec_step = <20>;
			oplus_spec,dec-vol-cc-full-thr = <0 400 600 800 1000 1200>;
			oplus_spec,dec-vol-fv-full-mv = <0 20 20 40 40 40>;
			oplus_spec,batt-them-thr = <(-100) 0 50 120 160 350 450 530>;
			oplus_spec,iterm-ma = <308>;
			oplus_spec,removed_bat_decidegc = <390>; /*-39 degree*/
			oplus_spec,fv-mv = <4450 4450 4450 4450 4450 4450 4450 4130 4130>;
			oplus_spec,sw-fv-mv = <4400 4400 4400 4400 4400 4400 4400 4080 4080>;
			oplus_spec,hw-fv-inc-mv = <0 18 18 18 18 18 18 18 0>;
			oplus_spec,sw-over-fv-mv = <4460 4460 4460 4460 4460 4460 4460 4140 4140>;
			oplus_spec,sw-over-fv-dec-mv = <8>;
			oplus_spec,non-standard-sw-fv-mv = <3930>;
			oplus_spec,non-standard-fv-mv = <3980>;
			oplus_spec,non-standard-hw-fv-inc-mv = <18>;
			oplus_spec,non-standard-sw-over-fv-mv = <3990>;
			oplus_spec,non-standard-vbatdet-mv = <3680>;
			oplus_spec,wired-vbatdet-mv = <0 4150 4250 4350 4350 4350 4350 4030 0>;
			oplus_spec,fcc-gear-thr-mv = <4180>;
			oplus_spec,vbatt-ov-thr-mv = <4600>;
			oplus_spec,full_pre_ffc_judge;
			oplus_spec,full-pre-ffc-mv = <4445>;
			oplus_spec,vbat_uv_thr_mv = <3300>;
			oplus_spec,vbat_charging_uv_thr_mv = <3200>;
			/*If use subboard NTC as battery temp, config it as 20, otherwise 0 */
			oplus_spec,tbatt_power_off_cali_temp = <0>;
			oplus_spec,poweroff_high_batt_temp = <720>;
			oplus_spec,poweroff_emergency_batt_temp = <770>;
			oplus,ui_soc_decimal_speedmin = <20>;
			oplus,gauge_stuck_jump_support;
			oplus,gauge_stuck_threshold = <15>;
			oplus,gauge_stuck_time = <50>;
			oplus,smooth_switch;
			oplus,reserve_chg_soc = <2>;
			oplus,vooc_dis_show_ui_power;
			oplus_spec,batt_full_time = <300>;
		};
	};
	oplus_monitor: oplus,monitor {
		compatible = "oplus,monitor";
		oplus,topic-update-interval = <60000>;
		track,fast_chg_break_t_thd = <2500>;
		track,general_chg_break_t_thd = <300>;
		track,wired_max_power = <15000>;
		track,wired_fast_chg_scheme = <6>;
		track,gauge_status_ctrl;
		track,external_gauge_num = <1>;

		track,gauge_max_cell_vol = <4600>;
		track,gauge_max_charge_curr = <13000>;
		track,gauge_max_dischg_curr = <3000>;
		track,gauge_min_cell_temp = <30>;
		track,gauge_max_cell_temp = <57>;
		track,gauge_firmware_term_volt = <3100>;
		track,gauge_lifetime_support;
		track,track_ver = <TRACK_VER_4_0>;
	};
	oplus_smart_charge: oplus,smart_charge {
		compatible = "oplus,smart_charge";
	};
	oplus_cpa: oplus,cpa {
		compatible = "oplus,cpa";
		oplus,protocol_list = <CHG_PROTOCOL_PD 15>;
		oplus,default_protocol_list = <CHG_PROTOCOL_PD>;
	};
};
